# PADCFG_CTRL_MCU_PADCFG_CTRL_MMR_CFG0_04080000h register map
Vendor: Texas Instruments
Registers are 32-bit, access per field, reset 0x214007 unless marked. A register's access mark holds for its fields unless they carry their own. Offsets are as the file gives them; [hi:lo] are bit positions; {n}, {i} and the like mark numbered series.

## mcu_padcfg_ctrl_mmr_CFG0 (part 3 of 3)
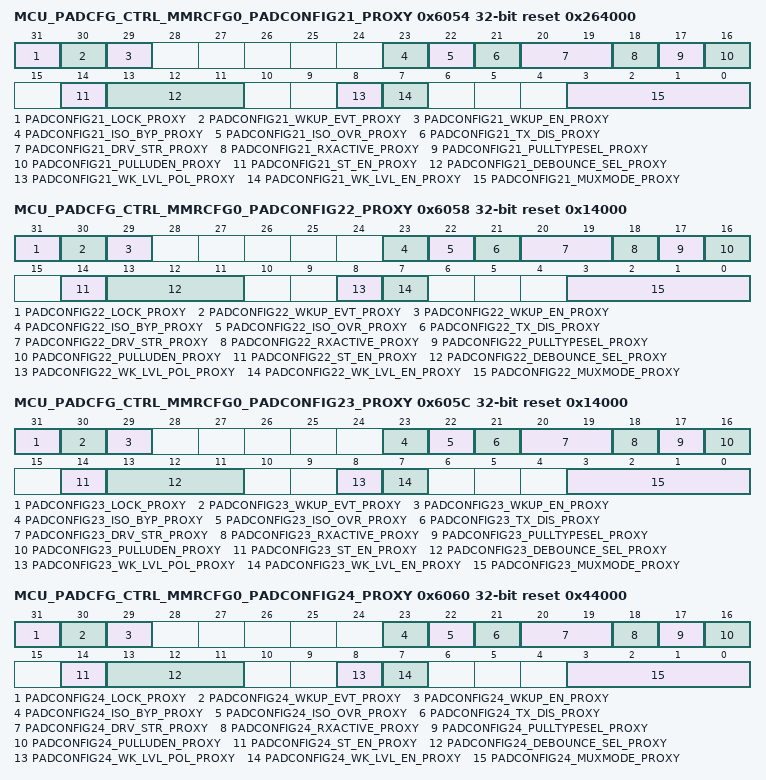
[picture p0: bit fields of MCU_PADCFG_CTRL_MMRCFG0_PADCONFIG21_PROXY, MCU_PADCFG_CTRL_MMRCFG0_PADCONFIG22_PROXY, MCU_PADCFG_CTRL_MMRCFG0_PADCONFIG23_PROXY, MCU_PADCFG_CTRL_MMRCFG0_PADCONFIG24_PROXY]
0x6054 MCU_PADCFG_CTRL_MMRCFG0_PADCONFIG21_PROXY reset 0x264000 — Register to control pin configuration and muxing
  [31] PADCONFIG21_LOCK_PROXY rw — Lock 0 - Padconfig register is unlocked 1 - Padconfig register is locked from further writes Reset Source: mod_por_rst_n
  [30] PADCONFIG21_WKUP_EVT_PROXY ro — Wakeup event status 0 - No wake event on pin 1 - Wake event occurred on pin Reset Source: mod_por_rst_n
  [29] PADCONFIG21_WKUP_EN_PROXY rw — Wakeup enable 0 - Wakeup operation disabled 1 - Wakeup operation enabled Reset Source: mod_por_rst_n
  [23] PADCONFIG21_ISO_BYP_PROXY rw — Isolation Bypass0 - IO isolation is preserved1 - IO isolation is bypassed Reset Source: mod_por_rst_n
  [22] PADCONFIG21_ISO_OVR_PROXY rw — Isolation Override0 - IO isolation is preserved1 - IO isolation is overridden Reset Source: mod_por_rst_n
  [21] PADCONFIG21_TX_DIS_PROXY rw — Driver Disable0 - Driver is enabled1 - Driver is disabled Reset Source: mod_por_rst_n
  [20:19] PADCONFIG21_DRV_STR_PROXY rw — Drive Strength Control . Selects the drive strength value for LVCMOS pins. (Does not apply to other pin types) Reset Source: mod_por_rst_n
  [18] PADCONFIG21_RXACTIVE_PROXY rw — Input enable for the Pad0 - Receiver disabled1 - Receiver enabled Reset Source: mod_por_rst_n
  [17] PADCONFIG21_PULLTYPESEL_PROXY rw — Pad Pullup / Pulldown type selection0 - Pulldown selected1 - Pullup selected Reset Source: mod_por_rst_n
  [16] PADCONFIG21_PULLUDEN_PROXY rw — Pad Pullup / Pulldown enable. This is an active low signal.0 - Pullup / Pulldown enabled1 - Pullup / Pulldown disabled Reset Source: mod_por_rst_n
  [14] PADCONFIG21_ST_EN_PROXY rw — Receiver Schmitt Trigger enable 0 - Schmitt trigger input disabled 1 - Schmitt trigger input enabled Reset Source: mod_por_rst_n
  [13:11] PADCONFIG21_DEBOUNCE_SEL_PROXY rw — Selects the debouce period for the pad.Field values (others are reserved):3'b000 - No debounce enabled 3'b001 - Use DBOUNCE_CFG1 register value3'b010 - Use DBOUNCE_CFG2 register value3'b011 - Use DBOUNCE_CFG3 register value3'b100 - Use DBOUNCE_CFG4 register value3'b101 - Use DBOUNCE_CFG5 register value3'b110 - Use DBOUNCE_CFG6 register value3'b'111 - Reserved Reset Source: mod_por_rst_n
  [8] PADCONFIG21_WK_LVL_POL_PROXY rw — Level Sensitive Wakeup PolarityThis bit is not relevant unless wk_lvl_en is set to 1'b1.0 - Low. A low (0) value on the pin causes a wakeup1 - High. A high (1) value on the pin causes a wakeup Reset Source: mod_por_rst_n
  [7] PADCONFIG21_WK_LVL_EN_PROXY rw — Level Sensitive Wakeup Enable0 - Disabled. Wakeup is triggered by change of the pin input value1 - Enabled. Wakeup is triggered when the pin matches the value specified by wk_lvl_pol. The chosen polarity must be maintained. (e.g. until wakeup completion is confirmed) Reset Source: mod_por_rst_n
  [3:0] PADCONFIG21_MUXMODE_PROXY rw — Pad functional signal mux selectionField values (others are reserved):4'h0 - Mux Mode 04'h1 - Mux Mode 14'h2 - Mux Mode 24'h3 - Mux Mode 34'h4 - Mux Mode 44'h5 - Mux Mode 54'h6 - Mux Mode 64'h7 - Mux Mode 74'h8 - Mux Mode 84'h9 - Mux Mode 94'hA - Mux Mode 104'hB - Mux Mode 114'hC - Mux Mode 124'hD - Mux Mode 134'hE - Mux Mode 144'hF - Mux Mode 15 Reset Source: mod_por_rst_n
0x6058 MCU_PADCFG_CTRL_MMRCFG0_PADCONFIG22_PROXY reset 0x14000 — Register to control pin configuration and muxing
  [31] PADCONFIG22_LOCK_PROXY rw — Lock 0 - Padconfig register is unlocked 1 - Padconfig register is locked from further writes Reset Source: mod_por_rst_n
  [30] PADCONFIG22_WKUP_EVT_PROXY ro — Wakeup event status 0 - No wake event on pin 1 - Wake event occurred on pin Reset Source: mod_por_rst_n
  [29] PADCONFIG22_WKUP_EN_PROXY rw — Wakeup enable 0 - Wakeup operation disabled 1 - Wakeup operation enabled Reset Source: mod_por_rst_n
  [23] PADCONFIG22_ISO_BYP_PROXY rw — Isolation Bypass0 - IO isolation is preserved1 - IO isolation is bypassed Reset Source: mod_por_rst_n
  [22] PADCONFIG22_ISO_OVR_PROXY rw — Isolation Override0 - IO isolation is preserved1 - IO isolation is overridden Reset Source: mod_por_rst_n
  [21] PADCONFIG22_TX_DIS_PROXY rw — Driver Disable0 - Driver is enabled1 - Driver is disabled Reset Source: mod_por_rst_n
  [20:19] PADCONFIG22_DRV_STR_PROXY rw — Drive Strength Control . Selects the drive strength value for LVCMOS pins. (Does not apply to other pin types) Reset Source: mod_por_rst_n
  [18] PADCONFIG22_RXACTIVE_PROXY rw — Input enable for the Pad0 - Receiver disabled1 - Receiver enabled Reset Source: mod_por_rst_n
  [17] PADCONFIG22_PULLTYPESEL_PROXY rw — Pad Pullup / Pulldown type selection0 - Pulldown selected1 - Pullup selected Reset Source: mod_por_rst_n
  [16] PADCONFIG22_PULLUDEN_PROXY rw — Pad Pullup / Pulldown enable. This is an active low signal.0 - Pullup / Pulldown enabled1 - Pullup / Pulldown disabled Reset Source: mod_por_rst_n
  [14] PADCONFIG22_ST_EN_PROXY rw — Receiver Schmitt Trigger enable 0 - Schmitt trigger input disabled 1 - Schmitt trigger input enabled Reset Source: mod_por_rst_n
  [13:11] PADCONFIG22_DEBOUNCE_SEL_PROXY rw — Selects the debouce period for the pad.Field values (others are reserved):3'b000 - No debounce enabled 3'b001 - Use DBOUNCE_CFG1 register value3'b010 - Use DBOUNCE_CFG2 register value3'b011 - Use DBOUNCE_CFG3 register value3'b100 - Use DBOUNCE_CFG4 register value3'b101 - Use DBOUNCE_CFG5 register value3'b110 - Use DBOUNCE_CFG6 register value3'b'111 - Reserved Reset Source: mod_por_rst_n
  [8] PADCONFIG22_WK_LVL_POL_PROXY rw — Level Sensitive Wakeup PolarityThis bit is not relevant unless wk_lvl_en is set to 1'b1.0 - Low. A low (0) value on the pin causes a wakeup1 - High. A high (1) value on the pin causes a wakeup Reset Source: mod_por_rst_n
  [7] PADCONFIG22_WK_LVL_EN_PROXY rw — Level Sensitive Wakeup Enable0 - Disabled. Wakeup is triggered by change of the pin input value1 - Enabled. Wakeup is triggered when the pin matches the value specified by wk_lvl_pol. The chosen polarity must be maintained. (e.g. until wakeup completion is confirmed) Reset Source: mod_por_rst_n
  [3:0] PADCONFIG22_MUXMODE_PROXY rw — Pad functional signal mux selectionField values (others are reserved):4'h0 - Mux Mode 04'h1 - Mux Mode 14'h2 - Mux Mode 24'h3 - Mux Mode 34'h4 - Mux Mode 44'h5 - Mux Mode 54'h6 - Mux Mode 64'h7 - Mux Mode 74'h8 - Mux Mode 84'h9 - Mux Mode 94'hA - Mux Mode 104'hB - Mux Mode 114'hC - Mux Mode 124'hD - Mux Mode 134'hE - Mux Mode 144'hF - Mux Mode 15 Reset Source: mod_por_rst_n
0x605C MCU_PADCFG_CTRL_MMRCFG0_PADCONFIG23_PROXY reset 0x14000 — Register to control pin configuration and muxing
  [31] PADCONFIG23_LOCK_PROXY rw — Lock 0 - Padconfig register is unlocked 1 - Padconfig register is locked from further writes Reset Source: mod_por_rst_n
  [30] PADCONFIG23_WKUP_EVT_PROXY ro — Wakeup event status 0 - No wake event on pin 1 - Wake event occurred on pin Reset Source: mod_por_rst_n
  [29] PADCONFIG23_WKUP_EN_PROXY rw — Wakeup enable 0 - Wakeup operation disabled 1 - Wakeup operation enabled Reset Source: mod_por_rst_n
  [23] PADCONFIG23_ISO_BYP_PROXY rw — Isolation Bypass0 - IO isolation is preserved1 - IO isolation is bypassed Reset Source: mod_por_rst_n
  [22] PADCONFIG23_ISO_OVR_PROXY rw — Isolation Override0 - IO isolation is preserved1 - IO isolation is overridden Reset Source: mod_por_rst_n
  [21] PADCONFIG23_TX_DIS_PROXY rw — Driver Disable0 - Driver is enabled1 - Driver is disabled Reset Source: mod_por_rst_n
  [20:19] PADCONFIG23_DRV_STR_PROXY rw — Drive Strength Control . Selects the drive strength value for LVCMOS pins. (Does not apply to other pin types) Reset Source: mod_por_rst_n
  [18] PADCONFIG23_RXACTIVE_PROXY rw — Input enable for the Pad0 - Receiver disabled1 - Receiver enabled Reset Source: mod_por_rst_n
  [17] PADCONFIG23_PULLTYPESEL_PROXY rw — Pad Pullup / Pulldown type selection0 - Pulldown selected1 - Pullup selected Reset Source: mod_por_rst_n
  [16] PADCONFIG23_PULLUDEN_PROXY rw — Pad Pullup / Pulldown enable. This is an active low signal.0 - Pullup / Pulldown enabled1 - Pullup / Pulldown disabled Reset Source: mod_por_rst_n
  [14] PADCONFIG23_ST_EN_PROXY rw — Receiver Schmitt Trigger enable 0 - Schmitt trigger input disabled 1 - Schmitt trigger input enabled Reset Source: mod_por_rst_n
  [13:11] PADCONFIG23_DEBOUNCE_SEL_PROXY rw — Selects the debouce period for the pad.Field values (others are reserved):3'b000 - No debounce enabled 3'b001 - Use DBOUNCE_CFG1 register value3'b010 - Use DBOUNCE_CFG2 register value3'b011 - Use DBOUNCE_CFG3 register value3'b100 - Use DBOUNCE_CFG4 register value3'b101 - Use DBOUNCE_CFG5 register value3'b110 - Use DBOUNCE_CFG6 register value3'b'111 - Reserved Reset Source: mod_por_rst_n
  [8] PADCONFIG23_WK_LVL_POL_PROXY rw — Level Sensitive Wakeup PolarityThis bit is not relevant unless wk_lvl_en is set to 1'b1.0 - Low. A low (0) value on the pin causes a wakeup1 - High. A high (1) value on the pin causes a wakeup Reset Source: mod_por_rst_n
  [7] PADCONFIG23_WK_LVL_EN_PROXY rw — Level Sensitive Wakeup Enable0 - Disabled. Wakeup is triggered by change of the pin input value1 - Enabled. Wakeup is triggered when the pin matches the value specified by wk_lvl_pol. The chosen polarity must be maintained. (e.g. until wakeup completion is confirmed) Reset Source: mod_por_rst_n
  [3:0] PADCONFIG23_MUXMODE_PROXY rw — Pad functional signal mux selectionField values (others are reserved):4'h0 - Mux Mode 04'h1 - Mux Mode 14'h2 - Mux Mode 24'h3 - Mux Mode 34'h4 - Mux Mode 44'h5 - Mux Mode 54'h6 - Mux Mode 64'h7 - Mux Mode 74'h8 - Mux Mode 84'h9 - Mux Mode 94'hA - Mux Mode 104'hB - Mux Mode 114'hC - Mux Mode 124'hD - Mux Mode 134'hE - Mux Mode 144'hF - Mux Mode 15 Reset Source: mod_por_rst_n
0x6060 MCU_PADCFG_CTRL_MMRCFG0_PADCONFIG24_PROXY reset 0x44000 — Register to control pin configuration and muxing
  [31] PADCONFIG24_LOCK_PROXY rw — Lock 0 - Padconfig register is unlocked 1 - Padconfig register is locked from further writes Reset Source: mod_por_rst_n
  [30] PADCONFIG24_WKUP_EVT_PROXY ro — Wakeup event status 0 - No wake event on pin 1 - Wake event occurred on pin Reset Source: mod_por_rst_n
  [29] PADCONFIG24_WKUP_EN_PROXY rw — Wakeup enable 0 - Wakeup operation disabled 1 - Wakeup operation enabled Reset Source: mod_por_rst_n
  [23] PADCONFIG24_ISO_BYP_PROXY rw — Isolation Bypass0 - IO isolation is preserved1 - IO isolation is bypassed Reset Source: mod_por_rst_n
  [22] PADCONFIG24_ISO_OVR_PROXY rw — Isolation Override0 - IO isolation is preserved1 - IO isolation is overridden Reset Source: mod_por_rst_n
  [21] PADCONFIG24_TX_DIS_PROXY rw — Driver Disable0 - Driver is enabled1 - Driver is disabled Reset Source: mod_por_rst_n
  [20:19] PADCONFIG24_DRV_STR_PROXY rw — Drive Strength Control . Selects the drive strength value for LVCMOS pins. (Does not apply to other pin types) Reset Source: mod_por_rst_n
  [18] PADCONFIG24_RXACTIVE_PROXY rw — Input enable for the Pad0 - Receiver disabled1 - Receiver enabled Reset Source: mod_por_rst_n
  [17] PADCONFIG24_PULLTYPESEL_PROXY rw — Pad Pullup / Pulldown type selection0 - Pulldown selected1 - Pullup selected Reset Source: mod_por_rst_n
  [16] PADCONFIG24_PULLUDEN_PROXY rw — Pad Pullup / Pulldown enable. This is an active low signal.0 - Pullup / Pulldown enabled1 - Pullup / Pulldown disabled Reset Source: mod_por_rst_n
  [14] PADCONFIG24_ST_EN_PROXY rw — Receiver Schmitt Trigger enable 0 - Schmitt trigger input disabled 1 - Schmitt trigger input enabled Reset Source: mod_por_rst_n
  [13:11] PADCONFIG24_DEBOUNCE_SEL_PROXY rw — Selects the debouce period for the pad.Field values (others are reserved):3'b000 - No debounce enabled 3'b001 - Use DBOUNCE_CFG1 register value3'b010 - Use DBOUNCE_CFG2 register value3'b011 - Use DBOUNCE_CFG3 register value3'b100 - Use DBOUNCE_CFG4 register value3'b101 - Use DBOUNCE_CFG5 register value3'b110 - Use DBOUNCE_CFG6 register value3'b'111 - Reserved Reset Source: mod_por_rst_n
  [8] PADCONFIG24_WK_LVL_POL_PROXY rw — Level Sensitive Wakeup PolarityThis bit is not relevant unless wk_lvl_en is set to 1'b1.0 - Low. A low (0) value on the pin causes a wakeup1 - High. A high (1) value on the pin causes a wakeup Reset Source: mod_por_rst_n
  [7] PADCONFIG24_WK_LVL_EN_PROXY rw — Level Sensitive Wakeup Enable0 - Disabled. Wakeup is triggered by change of the pin input value1 - Enabled. Wakeup is triggered when the pin matches the value specified by wk_lvl_pol. The chosen polarity must be maintained. (e.g. until wakeup completion is confirmed) Reset Source: mod_por_rst_n
  [3:0] PADCONFIG24_MUXMODE_PROXY rw — Pad functional signal mux selectionField values (others are reserved):4'h0 - Mux Mode 04'h1 - Mux Mode 14'h2 - Mux Mode 24'h3 - Mux Mode 34'h4 - Mux Mode 44'h5 - Mux Mode 54'h6 - Mux Mode 64'h7 - Mux Mode 74'h8 - Mux Mode 84'h9 - Mux Mode 94'hA - Mux Mode 104'hB - Mux Mode 114'hC - Mux Mode 124'hD - Mux Mode 134'hE - Mux Mode 144'hF - Mux Mode 15 Reset Source: mod_por_rst_n
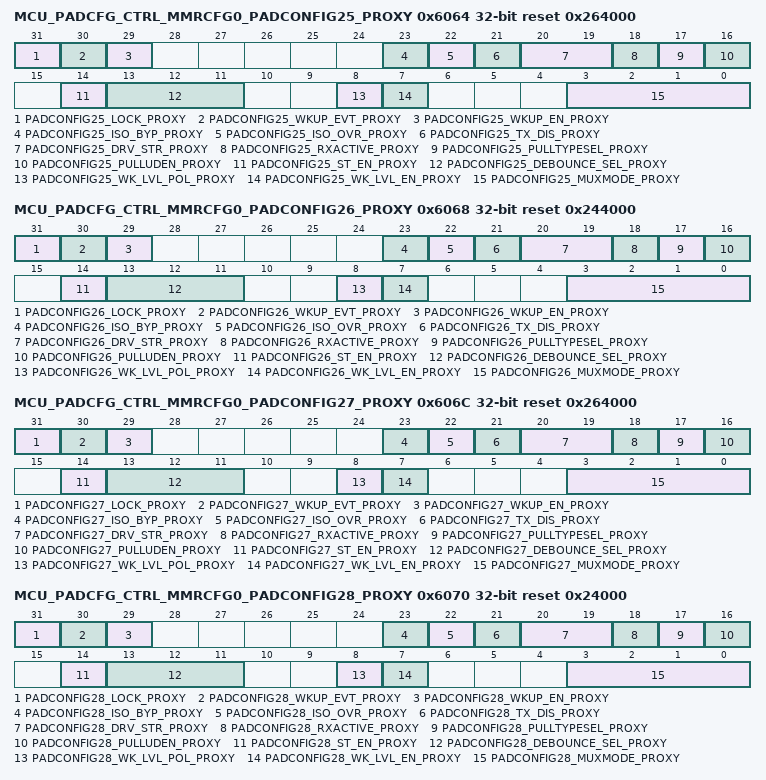
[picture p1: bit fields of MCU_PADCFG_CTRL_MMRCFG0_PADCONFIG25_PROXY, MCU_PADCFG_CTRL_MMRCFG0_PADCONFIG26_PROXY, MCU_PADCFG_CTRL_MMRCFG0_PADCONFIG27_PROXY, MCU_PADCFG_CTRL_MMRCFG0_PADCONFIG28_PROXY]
0x6064 MCU_PADCFG_CTRL_MMRCFG0_PADCONFIG25_PROXY reset 0x264000 — Register to control pin configuration and muxing
  [31] PADCONFIG25_LOCK_PROXY rw — Lock 0 - Padconfig register is unlocked 1 - Padconfig register is locked from further writes Reset Source: mod_por_rst_n
  [30] PADCONFIG25_WKUP_EVT_PROXY ro — Wakeup event status 0 - No wake event on pin 1 - Wake event occurred on pin Reset Source: mod_por_rst_n
  [29] PADCONFIG25_WKUP_EN_PROXY rw — Wakeup enable 0 - Wakeup operation disabled 1 - Wakeup operation enabled Reset Source: mod_por_rst_n
  [23] PADCONFIG25_ISO_BYP_PROXY rw — Isolation Bypass0 - IO isolation is preserved1 - IO isolation is bypassed Reset Source: mod_por_rst_n
  [22] PADCONFIG25_ISO_OVR_PROXY rw — Isolation Override0 - IO isolation is preserved1 - IO isolation is overridden Reset Source: mod_por_rst_n
  [21] PADCONFIG25_TX_DIS_PROXY rw — Driver Disable0 - Driver is enabled1 - Driver is disabled Reset Source: mod_por_rst_n
  [20:19] PADCONFIG25_DRV_STR_PROXY rw — Drive Strength Control . Selects the drive strength value for LVCMOS pins. (Does not apply to other pin types) Reset Source: mod_por_rst_n
  [18] PADCONFIG25_RXACTIVE_PROXY rw — Input enable for the Pad0 - Receiver disabled1 - Receiver enabled Reset Source: mod_por_rst_n
  [17] PADCONFIG25_PULLTYPESEL_PROXY rw — Pad Pullup / Pulldown type selection0 - Pulldown selected1 - Pullup selected Reset Source: mod_por_rst_n
  [16] PADCONFIG25_PULLUDEN_PROXY rw — Pad Pullup / Pulldown enable. This is an active low signal.0 - Pullup / Pulldown enabled1 - Pullup / Pulldown disabled Reset Source: mod_por_rst_n
  [14] PADCONFIG25_ST_EN_PROXY rw — Receiver Schmitt Trigger enable 0 - Schmitt trigger input disabled 1 - Schmitt trigger input enabled Reset Source: mod_por_rst_n
  [13:11] PADCONFIG25_DEBOUNCE_SEL_PROXY rw — Selects the debouce period for the pad.Field values (others are reserved):3'b000 - No debounce enabled 3'b001 - Use DBOUNCE_CFG1 register value3'b010 - Use DBOUNCE_CFG2 register value3'b011 - Use DBOUNCE_CFG3 register value3'b100 - Use DBOUNCE_CFG4 register value3'b101 - Use DBOUNCE_CFG5 register value3'b110 - Use DBOUNCE_CFG6 register value3'b'111 - Reserved Reset Source: mod_por_rst_n
  [8] PADCONFIG25_WK_LVL_POL_PROXY rw — Level Sensitive Wakeup PolarityThis bit is not relevant unless wk_lvl_en is set to 1'b1.0 - Low. A low (0) value on the pin causes a wakeup1 - High. A high (1) value on the pin causes a wakeup Reset Source: mod_por_rst_n
  [7] PADCONFIG25_WK_LVL_EN_PROXY rw — Level Sensitive Wakeup Enable0 - Disabled. Wakeup is triggered by change of the pin input value1 - Enabled. Wakeup is triggered when the pin matches the value specified by wk_lvl_pol. The chosen polarity must be maintained. (e.g. until wakeup completion is confirmed) Reset Source: mod_por_rst_n
  [3:0] PADCONFIG25_MUXMODE_PROXY rw — Pad functional signal mux selectionField values (others are reserved):4'h0 - Mux Mode 04'h1 - Mux Mode 14'h2 - Mux Mode 24'h3 - Mux Mode 34'h4 - Mux Mode 44'h5 - Mux Mode 54'h6 - Mux Mode 64'h7 - Mux Mode 74'h8 - Mux Mode 84'h9 - Mux Mode 94'hA - Mux Mode 104'hB - Mux Mode 114'hC - Mux Mode 124'hD - Mux Mode 134'hE - Mux Mode 144'hF - Mux Mode 15 Reset Source: mod_por_rst_n
0x6068 MCU_PADCFG_CTRL_MMRCFG0_PADCONFIG26_PROXY reset 0x244000 — Register to control pin configuration and muxing
  [31] PADCONFIG26_LOCK_PROXY rw — Lock 0 - Padconfig register is unlocked 1 - Padconfig register is locked from further writes Reset Source: mod_por_rst_n
  [30] PADCONFIG26_WKUP_EVT_PROXY ro — Wakeup event status 0 - No wake event on pin 1 - Wake event occurred on pin Reset Source: mod_por_rst_n
  [29] PADCONFIG26_WKUP_EN_PROXY rw — Wakeup enable 0 - Wakeup operation disabled 1 - Wakeup operation enabled Reset Source: mod_por_rst_n
  [23] PADCONFIG26_ISO_BYP_PROXY rw — Isolation Bypass0 - IO isolation is preserved1 - IO isolation is bypassed Reset Source: mod_por_rst_n
  [22] PADCONFIG26_ISO_OVR_PROXY rw — Isolation Override0 - IO isolation is preserved1 - IO isolation is overridden Reset Source: mod_por_rst_n
  [21] PADCONFIG26_TX_DIS_PROXY rw — Driver Disable0 - Driver is enabled1 - Driver is disabled Reset Source: mod_por_rst_n
  [20:19] PADCONFIG26_DRV_STR_PROXY rw — Drive Strength Control . Selects the drive strength value for LVCMOS pins. (Does not apply to other pin types) Reset Source: mod_por_rst_n
  [18] PADCONFIG26_RXACTIVE_PROXY rw — Input enable for the Pad0 - Receiver disabled1 - Receiver enabled Reset Source: mod_por_rst_n
  [17] PADCONFIG26_PULLTYPESEL_PROXY rw — Pad Pullup / Pulldown type selection0 - Pulldown selected1 - Pullup selected Reset Source: mod_por_rst_n
  [16] PADCONFIG26_PULLUDEN_PROXY rw — Pad Pullup / Pulldown enable. This is an active low signal.0 - Pullup / Pulldown enabled1 - Pullup / Pulldown disabled Reset Source: mod_por_rst_n
  [14] PADCONFIG26_ST_EN_PROXY rw — Receiver Schmitt Trigger enable 0 - Schmitt trigger input disabled 1 - Schmitt trigger input enabled Reset Source: mod_por_rst_n
  [13:11] PADCONFIG26_DEBOUNCE_SEL_PROXY rw — Selects the debouce period for the pad.Field values (others are reserved):3'b000 - No debounce enabled 3'b001 - Use DBOUNCE_CFG1 register value3'b010 - Use DBOUNCE_CFG2 register value3'b011 - Use DBOUNCE_CFG3 register value3'b100 - Use DBOUNCE_CFG4 register value3'b101 - Use DBOUNCE_CFG5 register value3'b110 - Use DBOUNCE_CFG6 register value3'b'111 - Reserved Reset Source: mod_por_rst_n
  [8] PADCONFIG26_WK_LVL_POL_PROXY rw — Level Sensitive Wakeup PolarityThis bit is not relevant unless wk_lvl_en is set to 1'b1.0 - Low. A low (0) value on the pin causes a wakeup1 - High. A high (1) value on the pin causes a wakeup Reset Source: mod_por_rst_n
  [7] PADCONFIG26_WK_LVL_EN_PROXY rw — Level Sensitive Wakeup Enable0 - Disabled. Wakeup is triggered by change of the pin input value1 - Enabled. Wakeup is triggered when the pin matches the value specified by wk_lvl_pol. The chosen polarity must be maintained. (e.g. until wakeup completion is confirmed) Reset Source: mod_por_rst_n
  [3:0] PADCONFIG26_MUXMODE_PROXY rw — Pad functional signal mux selectionField values (others are reserved):4'h0 - Mux Mode 04'h1 - Mux Mode 14'h2 - Mux Mode 24'h3 - Mux Mode 34'h4 - Mux Mode 44'h5 - Mux Mode 54'h6 - Mux Mode 64'h7 - Mux Mode 74'h8 - Mux Mode 84'h9 - Mux Mode 94'hA - Mux Mode 104'hB - Mux Mode 114'hC - Mux Mode 124'hD - Mux Mode 134'hE - Mux Mode 144'hF - Mux Mode 15 Reset Source: mod_por_rst_n
0x606C MCU_PADCFG_CTRL_MMRCFG0_PADCONFIG27_PROXY reset 0x264000 — Register to control pin configuration and muxing
  [31] PADCONFIG27_LOCK_PROXY rw — Lock 0 - Padconfig register is unlocked 1 - Padconfig register is locked from further writes Reset Source: mod_por_rst_n
  [30] PADCONFIG27_WKUP_EVT_PROXY ro — Wakeup event status 0 - No wake event on pin 1 - Wake event occurred on pin Reset Source: mod_por_rst_n
  [29] PADCONFIG27_WKUP_EN_PROXY rw — Wakeup enable 0 - Wakeup operation disabled 1 - Wakeup operation enabled Reset Source: mod_por_rst_n
  [23] PADCONFIG27_ISO_BYP_PROXY rw — Isolation Bypass0 - IO isolation is preserved1 - IO isolation is bypassed Reset Source: mod_por_rst_n
  [22] PADCONFIG27_ISO_OVR_PROXY rw — Isolation Override0 - IO isolation is preserved1 - IO isolation is overridden Reset Source: mod_por_rst_n
  [21] PADCONFIG27_TX_DIS_PROXY rw — Driver Disable0 - Driver is enabled1 - Driver is disabled Reset Source: mod_por_rst_n
  [20:19] PADCONFIG27_DRV_STR_PROXY rw — Drive Strength Control . Selects the drive strength value for LVCMOS pins. (Does not apply to other pin types) Reset Source: mod_por_rst_n
  [18] PADCONFIG27_RXACTIVE_PROXY rw — Input enable for the Pad0 - Receiver disabled1 - Receiver enabled Reset Source: mod_por_rst_n
  [17] PADCONFIG27_PULLTYPESEL_PROXY rw — Pad Pullup / Pulldown type selection0 - Pulldown selected1 - Pullup selected Reset Source: mod_por_rst_n
  [16] PADCONFIG27_PULLUDEN_PROXY rw — Pad Pullup / Pulldown enable. This is an active low signal.0 - Pullup / Pulldown enabled1 - Pullup / Pulldown disabled Reset Source: mod_por_rst_n
  [14] PADCONFIG27_ST_EN_PROXY rw — Receiver Schmitt Trigger enable 0 - Schmitt trigger input disabled 1 - Schmitt trigger input enabled Reset Source: mod_por_rst_n
  [13:11] PADCONFIG27_DEBOUNCE_SEL_PROXY rw — Selects the debouce period for the pad.Field values (others are reserved):3'b000 - No debounce enabled 3'b001 - Use DBOUNCE_CFG1 register value3'b010 - Use DBOUNCE_CFG2 register value3'b011 - Use DBOUNCE_CFG3 register value3'b100 - Use DBOUNCE_CFG4 register value3'b101 - Use DBOUNCE_CFG5 register value3'b110 - Use DBOUNCE_CFG6 register value3'b'111 - Reserved Reset Source: mod_por_rst_n
  [8] PADCONFIG27_WK_LVL_POL_PROXY rw — Level Sensitive Wakeup PolarityThis bit is not relevant unless wk_lvl_en is set to 1'b1.0 - Low. A low (0) value on the pin causes a wakeup1 - High. A high (1) value on the pin causes a wakeup Reset Source: mod_por_rst_n
  [7] PADCONFIG27_WK_LVL_EN_PROXY rw — Level Sensitive Wakeup Enable0 - Disabled. Wakeup is triggered by change of the pin input value1 - Enabled. Wakeup is triggered when the pin matches the value specified by wk_lvl_pol. The chosen polarity must be maintained. (e.g. until wakeup completion is confirmed) Reset Source: mod_por_rst_n
  [3:0] PADCONFIG27_MUXMODE_PROXY rw — Pad functional signal mux selectionField values (others are reserved):4'h0 - Mux Mode 04'h1 - Mux Mode 14'h2 - Mux Mode 24'h3 - Mux Mode 34'h4 - Mux Mode 44'h5 - Mux Mode 54'h6 - Mux Mode 64'h7 - Mux Mode 74'h8 - Mux Mode 84'h9 - Mux Mode 94'hA - Mux Mode 104'hB - Mux Mode 114'hC - Mux Mode 124'hD - Mux Mode 134'hE - Mux Mode 144'hF - Mux Mode 15 Reset Source: mod_por_rst_n
0x6070 MCU_PADCFG_CTRL_MMRCFG0_PADCONFIG28_PROXY reset 0x24000 — Register to control pin configuration and muxing
  [31] PADCONFIG28_LOCK_PROXY rw — Lock 0 - Padconfig register is unlocked 1 - Padconfig register is locked from further writes Reset Source: mod_por_rst_n
  [30] PADCONFIG28_WKUP_EVT_PROXY ro — Wakeup event status 0 - No wake event on pin 1 - Wake event occurred on pin Reset Source: mod_por_rst_n
  [29] PADCONFIG28_WKUP_EN_PROXY rw — Wakeup enable 0 - Wakeup operation disabled 1 - Wakeup operation enabled Reset Source: mod_por_rst_n
  [23] PADCONFIG28_ISO_BYP_PROXY rw — Isolation Bypass0 - IO isolation is preserved1 - IO isolation is bypassed Reset Source: mod_por_rst_n
  [22] PADCONFIG28_ISO_OVR_PROXY rw — Isolation Override0 - IO isolation is preserved1 - IO isolation is overridden Reset Source: mod_por_rst_n
  [21] PADCONFIG28_TX_DIS_PROXY rw — Driver Disable0 - Driver is enabled1 - Driver is disabled Reset Source: mod_por_rst_n
  [20:19] PADCONFIG28_DRV_STR_PROXY rw — Drive Strength Control . Selects the drive strength value for LVCMOS pins. (Does not apply to other pin types) Reset Source: mod_por_rst_n
  [18] PADCONFIG28_RXACTIVE_PROXY rw — Input enable for the Pad0 - Receiver disabled1 - Receiver enabled Reset Source: mod_por_rst_n
  [17] PADCONFIG28_PULLTYPESEL_PROXY rw — Pad Pullup / Pulldown type selection0 - Pulldown selected1 - Pullup selected Reset Source: mod_por_rst_n
  [16] PADCONFIG28_PULLUDEN_PROXY rw — Pad Pullup / Pulldown enable. This is an active low signal.0 - Pullup / Pulldown enabled1 - Pullup / Pulldown disabled Reset Source: mod_por_rst_n
  [14] PADCONFIG28_ST_EN_PROXY rw — Receiver Schmitt Trigger enable 0 - Schmitt trigger input disabled 1 - Schmitt trigger input enabled Reset Source: mod_por_rst_n
  [13:11] PADCONFIG28_DEBOUNCE_SEL_PROXY rw — Selects the debouce period for the pad.Field values (others are reserved):3'b000 - No debounce enabled 3'b001 - Use DBOUNCE_CFG1 register value3'b010 - Use DBOUNCE_CFG2 register value3'b011 - Use DBOUNCE_CFG3 register value3'b100 - Use DBOUNCE_CFG4 register value3'b101 - Use DBOUNCE_CFG5 register value3'b110 - Use DBOUNCE_CFG6 register value3'b'111 - Reserved Reset Source: mod_por_rst_n
  [8] PADCONFIG28_WK_LVL_POL_PROXY rw — Level Sensitive Wakeup PolarityThis bit is not relevant unless wk_lvl_en is set to 1'b1.0 - Low. A low (0) value on the pin causes a wakeup1 - High. A high (1) value on the pin causes a wakeup Reset Source: mod_por_rst_n
  [7] PADCONFIG28_WK_LVL_EN_PROXY rw — Level Sensitive Wakeup Enable0 - Disabled. Wakeup is triggered by change of the pin input value1 - Enabled. Wakeup is triggered when the pin matches the value specified by wk_lvl_pol. The chosen polarity must be maintained. (e.g. until wakeup completion is confirmed) Reset Source: mod_por_rst_n
  [3:0] PADCONFIG28_MUXMODE_PROXY rw — Pad functional signal mux selectionField values (others are reserved):4'h0 - Mux Mode 04'h1 - Mux Mode 14'h2 - Mux Mode 24'h3 - Mux Mode 34'h4 - Mux Mode 44'h5 - Mux Mode 54'h6 - Mux Mode 64'h7 - Mux Mode 74'h8 - Mux Mode 84'h9 - Mux Mode 94'hA - Mux Mode 104'hB - Mux Mode 114'hC - Mux Mode 124'hD - Mux Mode 134'hE - Mux Mode 144'hF - Mux Mode 15 Reset Source: mod_por_rst_n
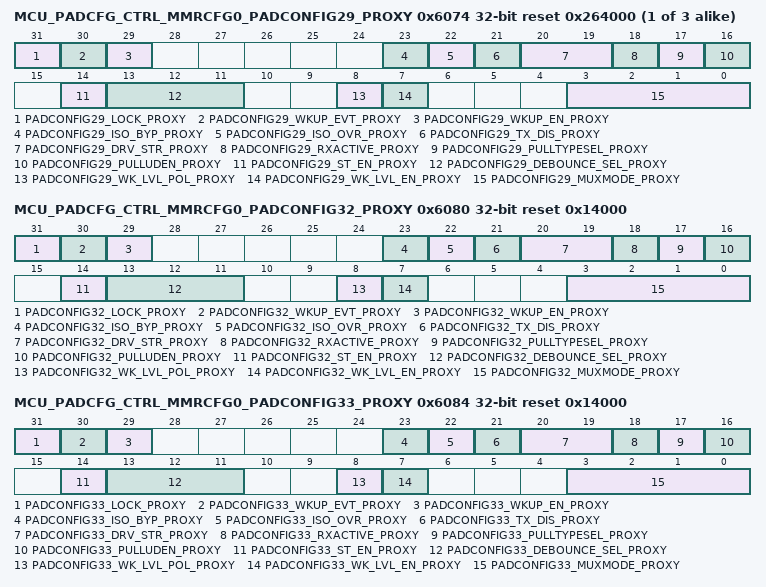
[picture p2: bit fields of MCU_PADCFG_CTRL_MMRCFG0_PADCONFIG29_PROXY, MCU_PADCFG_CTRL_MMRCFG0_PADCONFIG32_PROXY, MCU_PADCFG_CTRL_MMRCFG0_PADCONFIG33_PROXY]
{0x6000+4i} MCU_PADCFG_CTRL_MMRCFG0_PADCONFIG{i}_PROXY reset 0x264000 (i=29..31) — Register to control pin configuration and muxing
  [31] PADCONFIG{i}_LOCK_PROXY rw — Lock 0 - Padconfig register is unlocked 1 - Padconfig register is locked from further writes Reset Source: mod_por_rst_n
  [30] PADCONFIG{i}_WKUP_EVT_PROXY ro — Wakeup event status 0 - No wake event on pin 1 - Wake event occurred on pin Reset Source: mod_por_rst_n
  [29] PADCONFIG{i}_WKUP_EN_PROXY rw — Wakeup enable 0 - Wakeup operation disabled 1 - Wakeup operation enabled Reset Source: mod_por_rst_n
  [23] PADCONFIG{i}_ISO_BYP_PROXY rw — Isolation Bypass0 - IO isolation is preserved1 - IO isolation is bypassed Reset Source: mod_por_rst_n
  [22] PADCONFIG{i}_ISO_OVR_PROXY rw — Isolation Override0 - IO isolation is preserved1 - IO isolation is overridden Reset Source: mod_por_rst_n
  [21] PADCONFIG{i}_TX_DIS_PROXY rw — Driver Disable0 - Driver is enabled1 - Driver is disabled Reset Source: mod_por_rst_n
  [20:19] PADCONFIG{i}_DRV_STR_PROXY rw — Drive Strength Control . Selects the drive strength value for LVCMOS pins. (Does not apply to other pin types) Reset Source: mod_por_rst_n
  [18] PADCONFIG{i}_RXACTIVE_PROXY rw — Input enable for the Pad0 - Receiver disabled1 - Receiver enabled Reset Source: mod_por_rst_n
  [17] PADCONFIG{i}_PULLTYPESEL_PROXY rw — Pad Pullup / Pulldown type selection0 - Pulldown selected1 - Pullup selected Reset Source: mod_por_rst_n
  [16] PADCONFIG{i}_PULLUDEN_PROXY rw — Pad Pullup / Pulldown enable. This is an active low signal.0 - Pullup / Pulldown enabled1 - Pullup / Pulldown disabled Reset Source: mod_por_rst_n
  [14] PADCONFIG{i}_ST_EN_PROXY rw — Receiver Schmitt Trigger enable 0 - Schmitt trigger input disabled 1 - Schmitt trigger input enabled Reset Source: mod_por_rst_n
  [13:11] PADCONFIG{i}_DEBOUNCE_SEL_PROXY rw — Selects the debouce period for the pad.Field values (others are reserved):3'b000 - No debounce enabled 3'b001 - Use DBOUNCE_CFG1 register value3'b010 - Use DBOUNCE_CFG2 register value3'b011 - Use DBOUNCE_CFG3 register value3'b100 - Use DBOUNCE_CFG4 register value3'b101 - Use DBOUNCE_CFG5 register value3'b110 - Use DBOUNCE_CFG6 register value3'b'111 - Reserved Reset Source: mod_por_rst_n
  [8] PADCONFIG{i}_WK_LVL_POL_PROXY rw — Level Sensitive Wakeup PolarityThis bit is not relevant unless wk_lvl_en is set to 1'b1.0 - Low. A low (0) value on the pin causes a wakeup1 - High. A high (1) value on the pin causes a wakeup Reset Source: mod_por_rst_n
  [7] PADCONFIG{i}_WK_LVL_EN_PROXY rw — Level Sensitive Wakeup Enable0 - Disabled. Wakeup is triggered by change of the pin input value1 - Enabled. Wakeup is triggered when the pin matches the value specified by wk_lvl_pol. The chosen polarity must be maintained. (e.g. until wakeup completion is confirmed) Reset Source: mod_por_rst_n
  [3:0] PADCONFIG{i}_MUXMODE_PROXY rw — Pad functional signal mux selectionField values (others are reserved):4'h0 - Mux Mode 04'h1 - Mux Mode 14'h2 - Mux Mode 24'h3 - Mux Mode 34'h4 - Mux Mode 44'h5 - Mux Mode 54'h6 - Mux Mode 64'h7 - Mux Mode 74'h8 - Mux Mode 84'h9 - Mux Mode 94'hA - Mux Mode 104'hB - Mux Mode 114'hC - Mux Mode 124'hD - Mux Mode 134'hE - Mux Mode 144'hF - Mux Mode 15 Reset Source: mod_por_rst_n
0x6080 MCU_PADCFG_CTRL_MMRCFG0_PADCONFIG32_PROXY reset 0x14000 — Register to control pin configuration and muxing
  [31] PADCONFIG32_LOCK_PROXY rw — Lock 0 - Padconfig register is unlocked 1 - Padconfig register is locked from further writes Reset Source: mod_por_rst_n
  [30] PADCONFIG32_WKUP_EVT_PROXY ro — Wakeup event status 0 - No wake event on pin 1 - Wake event occurred on pin Reset Source: mod_por_rst_n
  [29] PADCONFIG32_WKUP_EN_PROXY rw — Wakeup enable 0 - Wakeup operation disabled 1 - Wakeup operation enabled Reset Source: mod_por_rst_n
  [23] PADCONFIG32_ISO_BYP_PROXY rw — Isolation Bypass0 - IO isolation is preserved1 - IO isolation is bypassed Reset Source: mod_por_rst_n
  [22] PADCONFIG32_ISO_OVR_PROXY rw — Isolation Override0 - IO isolation is preserved1 - IO isolation is overridden Reset Source: mod_por_rst_n
  [21] PADCONFIG32_TX_DIS_PROXY rw — Driver Disable0 - Driver is enabled1 - Driver is disabled Reset Source: mod_por_rst_n
  [20:19] PADCONFIG32_DRV_STR_PROXY rw — Drive Strength Control . Selects the drive strength value for LVCMOS pins. (Does not apply to other pin types) Reset Source: mod_por_rst_n
  [18] PADCONFIG32_RXACTIVE_PROXY rw — Input enable for the Pad0 - Receiver disabled1 - Receiver enabled Reset Source: mod_por_rst_n
  [17] PADCONFIG32_PULLTYPESEL_PROXY rw — Pad Pullup / Pulldown type selection0 - Pulldown selected1 - Pullup selected Reset Source: mod_por_rst_n
  [16] PADCONFIG32_PULLUDEN_PROXY rw — Pad Pullup / Pulldown enable. This is an active low signal.0 - Pullup / Pulldown enabled1 - Pullup / Pulldown disabled Reset Source: mod_por_rst_n
  [14] PADCONFIG32_ST_EN_PROXY rw — Receiver Schmitt Trigger enable 0 - Schmitt trigger input disabled 1 - Schmitt trigger input enabled Reset Source: mod_por_rst_n
  [13:11] PADCONFIG32_DEBOUNCE_SEL_PROXY rw — Selects the debouce period for the pad.Field values (others are reserved):3'b000 - No debounce enabled 3'b001 - Use DBOUNCE_CFG1 register value3'b010 - Use DBOUNCE_CFG2 register value3'b011 - Use DBOUNCE_CFG3 register value3'b100 - Use DBOUNCE_CFG4 register value3'b101 - Use DBOUNCE_CFG5 register value3'b110 - Use DBOUNCE_CFG6 register value3'b'111 - Reserved Reset Source: mod_por_rst_n
  [8] PADCONFIG32_WK_LVL_POL_PROXY rw — Level Sensitive Wakeup PolarityThis bit is not relevant unless wk_lvl_en is set to 1'b1.0 - Low. A low (0) value on the pin causes a wakeup1 - High. A high (1) value on the pin causes a wakeup Reset Source: mod_por_rst_n
  [7] PADCONFIG32_WK_LVL_EN_PROXY rw — Level Sensitive Wakeup Enable0 - Disabled. Wakeup is triggered by change of the pin input value1 - Enabled. Wakeup is triggered when the pin matches the value specified by wk_lvl_pol. The chosen polarity must be maintained. (e.g. until wakeup completion is confirmed) Reset Source: mod_por_rst_n
  [3:0] PADCONFIG32_MUXMODE_PROXY rw — Pad functional signal mux selectionField values (others are reserved):4'h0 - Mux Mode 04'h1 - Mux Mode 14'h2 - Mux Mode 24'h3 - Mux Mode 34'h4 - Mux Mode 44'h5 - Mux Mode 54'h6 - Mux Mode 64'h7 - Mux Mode 74'h8 - Mux Mode 84'h9 - Mux Mode 94'hA - Mux Mode 104'hB - Mux Mode 114'hC - Mux Mode 124'hD - Mux Mode 134'hE - Mux Mode 144'hF - Mux Mode 15 Reset Source: mod_por_rst_n
0x6084 MCU_PADCFG_CTRL_MMRCFG0_PADCONFIG33_PROXY reset 0x14000 — Register to control pin configuration and muxing
  [31] PADCONFIG33_LOCK_PROXY rw — Lock 0 - Padconfig register is unlocked 1 - Padconfig register is locked from further writes Reset Source: mod_por_rst_n
  [30] PADCONFIG33_WKUP_EVT_PROXY ro — Wakeup event status 0 - No wake event on pin 1 - Wake event occurred on pin Reset Source: mod_por_rst_n
  [29] PADCONFIG33_WKUP_EN_PROXY rw — Wakeup enable 0 - Wakeup operation disabled 1 - Wakeup operation enabled Reset Source: mod_por_rst_n
  [23] PADCONFIG33_ISO_BYP_PROXY rw — Isolation Bypass0 - IO isolation is preserved1 - IO isolation is bypassed Reset Source: mod_por_rst_n
  [22] PADCONFIG33_ISO_OVR_PROXY rw — Isolation Override0 - IO isolation is preserved1 - IO isolation is overridden Reset Source: mod_por_rst_n
  [21] PADCONFIG33_TX_DIS_PROXY rw — Driver Disable0 - Driver is enabled1 - Driver is disabled Reset Source: mod_por_rst_n
  [20:19] PADCONFIG33_DRV_STR_PROXY rw — Drive Strength Control . Selects the drive strength value for LVCMOS pins. (Does not apply to other pin types) Reset Source: mod_por_rst_n
  [18] PADCONFIG33_RXACTIVE_PROXY rw — Input enable for the Pad0 - Receiver disabled1 - Receiver enabled Reset Source: mod_por_rst_n
  [17] PADCONFIG33_PULLTYPESEL_PROXY rw — Pad Pullup / Pulldown type selection0 - Pulldown selected1 - Pullup selected Reset Source: mod_por_rst_n
  [16] PADCONFIG33_PULLUDEN_PROXY rw — Pad Pullup / Pulldown enable. This is an active low signal.0 - Pullup / Pulldown enabled1 - Pullup / Pulldown disabled Reset Source: mod_por_rst_n
  [14] PADCONFIG33_ST_EN_PROXY rw — Receiver Schmitt Trigger enable 0 - Schmitt trigger input disabled 1 - Schmitt trigger input enabled Reset Source: mod_por_rst_n
  [13:11] PADCONFIG33_DEBOUNCE_SEL_PROXY rw — Selects the debouce period for the pad.Field values (others are reserved):3'b000 - No debounce enabled 3'b001 - Use DBOUNCE_CFG1 register value3'b010 - Use DBOUNCE_CFG2 register value3'b011 - Use DBOUNCE_CFG3 register value3'b100 - Use DBOUNCE_CFG4 register value3'b101 - Use DBOUNCE_CFG5 register value3'b110 - Use DBOUNCE_CFG6 register value3'b'111 - Reserved Reset Source: mod_por_rst_n
  [8] PADCONFIG33_WK_LVL_POL_PROXY rw — Level Sensitive Wakeup PolarityThis bit is not relevant unless wk_lvl_en is set to 1'b1.0 - Low. A low (0) value on the pin causes a wakeup1 - High. A high (1) value on the pin causes a wakeup Reset Source: mod_por_rst_n
  [7] PADCONFIG33_WK_LVL_EN_PROXY rw — Level Sensitive Wakeup Enable0 - Disabled. Wakeup is triggered by change of the pin input value1 - Enabled. Wakeup is triggered when the pin matches the value specified by wk_lvl_pol. The chosen polarity must be maintained. (e.g. until wakeup completion is confirmed) Reset Source: mod_por_rst_n
  [3:0] PADCONFIG33_MUXMODE_PROXY rw — Pad functional signal mux selectionField values (others are reserved):4'h0 - Mux Mode 04'h1 - Mux Mode 14'h2 - Mux Mode 24'h3 - Mux Mode 34'h4 - Mux Mode 44'h5 - Mux Mode 54'h6 - Mux Mode 64'h7 - Mux Mode 74'h8 - Mux Mode 84'h9 - Mux Mode 94'hA - Mux Mode 104'hB - Mux Mode 114'hC - Mux Mode 124'hD - Mux Mode 134'hE - Mux Mode 144'hF - Mux Mode 15 Reset Source: mod_por_rst_n
0x7008 MCU_PADCFG_CTRL_MMRCFG0_LOCK1_KICK0_PROXY rw reset 0x0
  [31:0] LOCK1_KICK0_PROXY — - KICK0 component Reset Source: mod_g_rst_n
0x700C MCU_PADCFG_CTRL_MMRCFG0_LOCK1_KICK1_PROXY rw reset 0x0
  [31:0] LOCK1_KICK1_PROXY — - KICK1 component Reset Source: mod_g_rst_n
0x7100 MCU_PADCFG_CTRL_MMRCFG0_CLAIMREG_P1_R0 rw reset 0x0
  [31:0] CLAIMREG_P1_R0 — Claim bits for Partition 1 Reset Source: mod_g_rst_n
0x7104 MCU_PADCFG_CTRL_MMRCFG0_CLAIMREG_P1_R1 rw reset 0x0
  [31:0] CLAIMREG_P1_R1 — Claim bits for Partition 1 Reset Source: mod_g_rst_n
